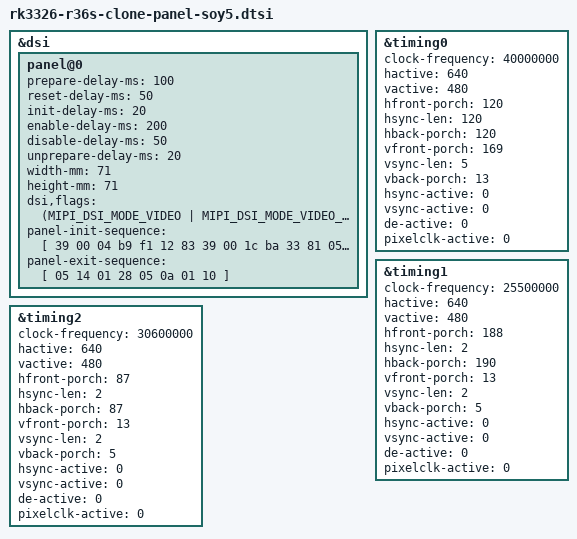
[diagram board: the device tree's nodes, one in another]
// SPDX-License-Identifier: (GPL-2.0+ OR MIT)
/*
 * EXPERIMENTAL - not tested on hardware by andr36oid. Keep a copy of the
 * files you replace so you can go back.
 *
 * Soy Sauce panel with the 19-command init sequence. Same values as
 * rk3326-r36s-android-panel5.dts; this copy is for the Soy Sauce board DTs.
 */

&dsi {
	panel@0 {
		prepare-delay-ms = <100>;
		reset-delay-ms = <50>;
		init-delay-ms = <20>;
		enable-delay-ms = <200>;
		disable-delay-ms = <50>;
		unprepare-delay-ms = <20>;
		width-mm = <71>;
		height-mm = <71>;
		dsi,flags = <(MIPI_DSI_MODE_VIDEO |
		      MIPI_DSI_MODE_VIDEO_BURST |
		      MIPI_DSI_MODE_EOT_PACKET |
		      MIPI_DSI_MODE_LPM)>;
		panel-init-sequence = [
			39 00 04 b9 f1 12 83
			39 00 1c ba 33 81 05 f9 0e 0e 20 00 00 00 00 00 00 00 44 25 00 91 0a 00 00 02 4f d1 00 00 37
			15 00 02 b8 25
			39 00 04 bf 02 11 00
			39 00 0b b3 0c 10 0a 50 03 ff 00 00 00 00
			39 00 0a c0 73 73 50 50 00 00 08 70 00
			15 00 02 bc 46
			15 00 02 cc 0b
			15 00 02 b4 80
			39 00 04 b2 00 13 f0
			39 00 0f e3 07 07 0b 0b 03 0b 00 00 00 00 ff 00 c0 10
			39 00 0d c1 53 00 1e 1e 77 e1 cc dd 67 77 33 33
			39 00 03 b5 10 10
			39 00 03 b6 6c 7c
			39 00 40 e9 08 00 0e 00 00 b0 b1 11 31 23 28 10 b0 b1 27 08 00 04 02 00 00 00 00 04 02 00 00 00 88 88 ba 60 24 08 88 88 88 88 88 88 88 ba 71 35 18 88 88 88 88 88 00 00 00 01 00 00 00 00 00 00 00 00 00
			39 00 3e ea 97 0a 82 02 13 07 00 00 00 00 00 00 80 88 ba 17 53 88 88 88 88 88 88 81 88 ba 06 42 88 88 88 88 88 88 23 10 00 02 80 00 00 00 00 00 00 00 00 00 00 00 00 00 00 00 00 00 00 00 00 00 00
			39 00 23 e0 00 07 0b 27 2d 3f 3b 37 05 0a 0b 0f 11 0f 12 12 18 00 07 0b 27 2d 3f 3b 37 05 0a 0b 0f 11 0f 12 12 18
			05 96 01 11
			05 32 01 29
		];
		panel-exit-sequence = [
			05 14 01 28
			05 0a 01 10
		];
	};
};

&timing0 {
	clock-frequency = <40000000>;
	hactive = <640>;
	vactive = <480>;
	hfront-porch = <120>;
	hsync-len = <120>;
	hback-porch = <120>;
	vfront-porch = <169>;	/* was 17: 77.7 Hz; 59.97 Hz, same pixel clock */
	vsync-len = <5>;
	vback-porch = <13>;
	hsync-active = <0>;
	vsync-active = <0>;
	de-active = <0>;
	pixelclk-active = <0>;
};

&timing1 {
	clock-frequency = <25500000>;
	hactive = <640>;
	vactive = <480>;
	hfront-porch = <188>;
	hsync-len = <2>;
	hback-porch = <190>;
	vfront-porch = <13>;
	vsync-len = <2>;
	vback-porch = <5>;
	hsync-active = <0>;
	vsync-active = <0>;
	de-active = <0>;
	pixelclk-active = <0>;
};

&timing2 {
	clock-frequency = <30600000>;
	hactive = <640>;
	vactive = <480>;
	hfront-porch = <87>;
	hsync-len = <2>;
	hback-porch = <87>;
	vfront-porch = <13>;
	vsync-len = <2>;
	vback-porch = <5>;
	hsync-active = <0>;
	vsync-active = <0>;
	de-active = <0>;
	pixelclk-active = <0>;
};
